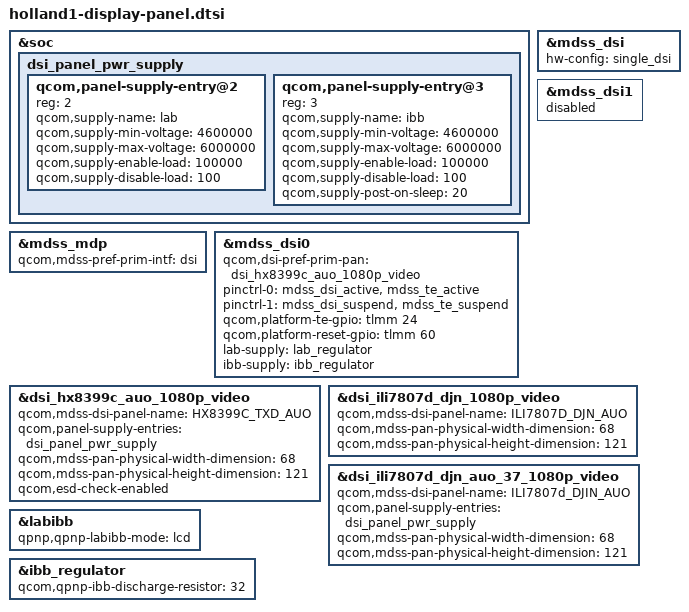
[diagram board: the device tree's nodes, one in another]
/*
 * Copyright (c) 2015-2016, The Linux Foundation. All rights reserved.
 *
 * Copyright (c) 2020, Shubham-Panwar.
 *
 * This program is free software; you can redistribute it and/or modify
 * it under the terms of the GNU General Public License version 2 and
 * only version 2 as published by the Free Software Foundation.
 *
 * This program is distributed in the hope that it will be useful,
 * but WITHOUT ANY WARRANTY; without even the implied warranty of
 * MERCHANTABILITY or FITNESS FOR A PARTICULAR PURPOSE.  See the
 * GNU General Public License for more details.
 */

#include "display-panels/dsi-panel-hx8399c-auo-1080p-video.dtsi"
#include "display-panels/dsi-panel-ili7807d-djn-1080p-video.dtsi"
#include "display-panels/dsi-panel-ili7807d-djn-auo-37-1080p-video.dtsi"
&soc {
	dsi_panel_pwr_supply: dsi_panel_pwr_supply {
		#address-cells = <1>;
		#size-cells = <0>;

		qcom,panel-supply-entry@2 {
			reg = <2>;
			qcom,supply-name = "lab";
			qcom,supply-min-voltage = <4600000>;
			qcom,supply-max-voltage = <6000000>;
			qcom,supply-enable-load = <100000>;
			qcom,supply-disable-load = <100>;
		};

		qcom,panel-supply-entry@3 {
			reg = <3>;
			qcom,supply-name = "ibb";
			qcom,supply-min-voltage = <4600000>;
			qcom,supply-max-voltage = <6000000>;
			qcom,supply-enable-load = <100000>;
			qcom,supply-disable-load = <100>;
			qcom,supply-post-on-sleep = <20>;
		};
	};
};

&mdss_mdp {
	qcom,mdss-pref-prim-intf = "dsi";
};

&mdss_dsi {
	hw-config = "single_dsi";
};

&mdss_dsi0 {
	qcom,dsi-pref-prim-pan = <&dsi_hx8399c_auo_1080p_video>;
	pinctrl-names = "mdss_default", "mdss_sleep";
	pinctrl-0 = <&mdss_dsi_active &mdss_te_active>;
	pinctrl-1 = <&mdss_dsi_suspend &mdss_te_suspend>;

	qcom,platform-te-gpio = <&tlmm 24 0>;
	qcom,platform-reset-gpio = <&tlmm 60 0>;
};
&mdss_dsi1 {
	status = "disabled";
};


&dsi_hx8399c_auo_1080p_video {
	qcom,mdss-dsi-panel-name = "HX8399C_TXD_AUO";
	qcom,panel-supply-entries = <&dsi_panel_pwr_supply>;
	qcom,mdss-pan-physical-width-dimension = <68>;
	qcom,mdss-pan-physical-height-dimension = <121>;
	qcom,esd-check-enabled;
};

/*djin 2*/
/*
&dsi_ili7807d_djn_1080p_video {
	qcom,esd-check-enabled;
	qcom,panel-supply-entries = <&dsi_panel_pwr_supply>;
};
*/
&dsi_ili7807d_djn_1080p_video {
	qcom,mdss-dsi-panel-name = "ILI7807D_DJN_AUO";
	qcom,mdss-pan-physical-width-dimension = <68>;
	qcom,mdss-pan-physical-height-dimension = <121>;
};


&dsi_ili7807d_djn_auo_37_1080p_video {
	qcom,mdss-dsi-panel-name = "ILI7807d_DJIN_AUO";
	qcom,panel-supply-entries = <&dsi_panel_pwr_supply>;
	qcom,mdss-pan-physical-width-dimension = <68>;
	qcom,mdss-pan-physical-height-dimension = <121>;
};

&mdss_dsi0 {
	lab-supply = <&lab_regulator>;
	ibb-supply = <&ibb_regulator>;
};

&labibb {
	status = "ok";
	qpnp,qpnp-labibb-mode = "lcd";
};

&ibb_regulator {
	qcom,qpnp-ibb-discharge-resistor = <32>;
};
